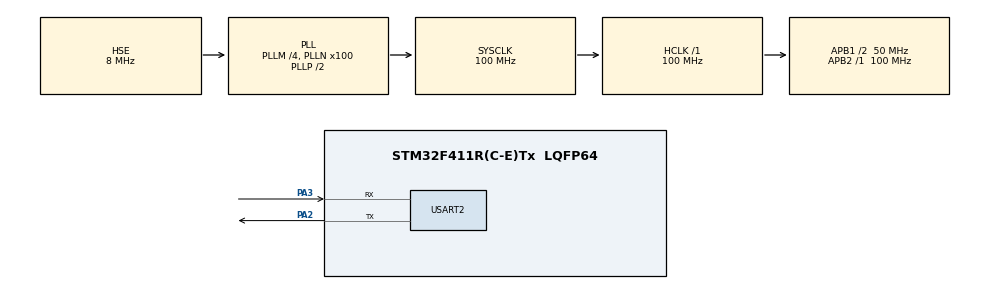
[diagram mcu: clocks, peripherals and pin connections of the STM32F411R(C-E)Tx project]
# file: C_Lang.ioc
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Mcu.Family=STM32F4
Mcu.Name=STM32F411R(C-E)Tx
Mcu.Package=LQFP64
NVIC.PriorityGroup=NVIC_PRIORITYGROUP_4
PA2.Mode=Asynchronous
PA2.Signal=USART2_TX
PA3.Mode=Asynchronous
PA3.Signal=USART2_RX
PH0\ -\ OSC_IN.Mode=HSE-External-Oscillator
PH0\ -\ OSC_IN.Signal=RCC_OSC_IN
PH1\ -\ OSC_OUT.Mode=HSE-External-Oscillator
PH1\ -\ OSC_OUT.Signal=RCC_OSC_OUT
ProjectManager.HeapSize=0x200
ProjectManager.StackSize=0x400
ProjectManager.TargetToolchain=STM32CubeIDE
RCC.48MHZClocksFreq_Value=50000000
RCC.AHBFreq_Value=100000000
RCC.APB1CLKDivider=RCC_HCLK_DIV2
RCC.APB1Freq_Value=50000000
RCC.APB1TimFreq_Value=100000000
RCC.APB2Freq_Value=100000000
RCC.APB2TimFreq_Value=100000000
RCC.CortexFreq_Value=100000000
RCC.HCLKFreq_Value=100000000
RCC.HSE_VALUE=8000000
RCC.HSI_VALUE=16000000
RCC.LSE_VALUE=32768
RCC.PLLM=4
RCC.PLLN=100
RCC.PLLSourceVirtual=RCC_PLLSOURCE_HSE
RCC.SYSCLKFreq_VALUE=100000000
RCC.SYSCLKSource=RCC_SYSCLKSOURCE_PLLCLK
RCC.VCOOutputFreq_Value=200000000
USART2.VirtualMode=VM_ASYNC
board=custom

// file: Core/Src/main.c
/* USER CODE BEGIN Header */
/**
 ******************************************************************************
 * @file           : main.c
 * @brief          : Main program body
 ******************************************************************************
 * @attention
 *
 * Copyright (c) 2026 STMicroelectronics.
 * All rights reserved.
 *
 * This software is licensed under terms that can be found in the LICENSE file
 * in the root directory of this software component.
 * If no LICENSE file comes with this software, it is provided AS-IS.
 *
 ******************************************************************************
 */
/* USER CODE END Header */
#include "main.h"

/* USER CODE BEGIN Includes */
#include <stdio.h>

/* USER CODE END Includes */

UART_HandleTypeDef huart2; // handler

void SystemClock_Config(void);
static void MX_GPIO_Init(void);
static void MX_USART2_UART_Init(void);

/* USER CODE BEGIN 0 */
int __io_putchar(int ch) {
	// print문이 어디를 통해서 나갈지 결정
	HAL_UART_Transmit(&huart2, (uint8_t*) &ch, 1, HAL_MAX_DELAY);
	return ch;
}
/* USER CODE END 0 */

int main(void) {

	/* MCU Configuration--------------------------------------------------------*/

	/* Reset of all peripherals, Initializes the Flash interface and the Systick. */
	HAL_Init();

	/* Configure the system clock */
	SystemClock_Config();

	/* Initialize all configured peripherals */
	MX_GPIO_Init();
	MX_USART2_UART_Init();

	/* Infinite loop */
	/* USER CODE BEGIN WHILE */

//	int iTrue, iFalse;
//	iTrue = 3 > 1;
//	iFalse = 3 < 1;
//
//	printf("iTrue: %d, iFalse: %d\n", iTrue, iFalse);
//
//	int age;
//	age = 0x12345678;
//
//	printf("hello STM32...!\n");
//	printf("long: %d, long long: %d\n", sizeof(long), sizeof(long long));
//	printf("float: %d, double: %d\n", sizeof(float), sizeof(double));
	// pointer
//	int age = 20;
//	int *p;
//
//	p = &age;
//
//	printf("age: %d, p: %h", age, p);
//
//	*p = 24;
//
//	printf("age: %d, p: %h", age, p);
	char *c;
	short *s;
	int *i;
	long long *l;

	printf("size of c: %d, s: %d, i: %d, l: %d\n", sizeof(c), sizeof(s),
			sizeof(i), sizeof(l));

	while (1) {
//		printf("%d, ", sizeof('A'));
//		printf("%d\n", sizeof("A"));
		/* USER CODE END WHILE */

	}
}

void SystemClock_Config(void) {
	RCC_OscInitTypeDef RCC_OscInitStruct = { 0 };
	RCC_ClkInitTypeDef RCC_ClkInitStruct = { 0 };

	/** Configure the main internal regulator output voltage
	 */
	__HAL_RCC_PWR_CLK_ENABLE();
	__HAL_PWR_VOLTAGESCALING_CONFIG(PWR_REGULATOR_VOLTAGE_SCALE1);

	/** Initializes the RCC Oscillators according to the specified parameters
	 * in the RCC_OscInitTypeDef structure.
	 */
	RCC_OscInitStruct.OscillatorType = RCC_OSCILLATORTYPE_HSE;
	RCC_OscInitStruct.HSEState = RCC_HSE_ON;
	RCC_OscInitStruct.PLL.PLLState = RCC_PLL_ON;
	RCC_OscInitStruct.PLL.PLLSource = RCC_PLLSOURCE_HSE;
	RCC_OscInitStruct.PLL.PLLM = 4;
	RCC_OscInitStruct.PLL.PLLN = 100;
	RCC_OscInitStruct.PLL.PLLP = RCC_PLLP_DIV2;
	RCC_OscInitStruct.PLL.PLLQ = 4;
	if (HAL_RCC_OscConfig(&RCC_OscInitStruct) != HAL_OK) {
		Error_Handler();
	}

	/** Initializes the CPU, AHB and APB buses clocks
	 */
	RCC_ClkInitStruct.ClockType = RCC_CLOCKTYPE_HCLK | RCC_CLOCKTYPE_SYSCLK
			| RCC_CLOCKTYPE_PCLK1 | RCC_CLOCKTYPE_PCLK2;
	RCC_ClkInitStruct.SYSCLKSource = RCC_SYSCLKSOURCE_PLLCLK;
	RCC_ClkInitStruct.AHBCLKDivider = RCC_SYSCLK_DIV1;
	RCC_ClkInitStruct.APB1CLKDivider = RCC_HCLK_DIV2;
	RCC_ClkInitStruct.APB2CLKDivider = RCC_HCLK_DIV1;

	if (HAL_RCC_ClockConfig(&RCC_ClkInitStruct, FLASH_LATENCY_3) != HAL_OK) {
		Error_Handler();
	}
}

static void MX_USART2_UART_Init(void) {

	huart2.Instance = USART2;
	huart2.Init.BaudRate = 115200;
	huart2.Init.WordLength = UART_WORDLENGTH_8B;
	huart2.Init.StopBits = UART_STOPBITS_1;
	huart2.Init.Parity = UART_PARITY_NONE;
	huart2.Init.Mode = UART_MODE_TX_RX;
	huart2.Init.HwFlowCtl = UART_HWCONTROL_NONE;
	huart2.Init.OverSampling = UART_OVERSAMPLING_16;
	if (HAL_UART_Init(&huart2) != HAL_OK) {
		Error_Handler();
	}

}

static void MX_GPIO_Init(void) {

	/* GPIO Ports Clock Enable */
	__HAL_RCC_GPIOH_CLK_ENABLE();
	__HAL_RCC_GPIOA_CLK_ENABLE();

}

void Error_Handler(void) {
	__disable_irq();
	while (1) {
	}
}
